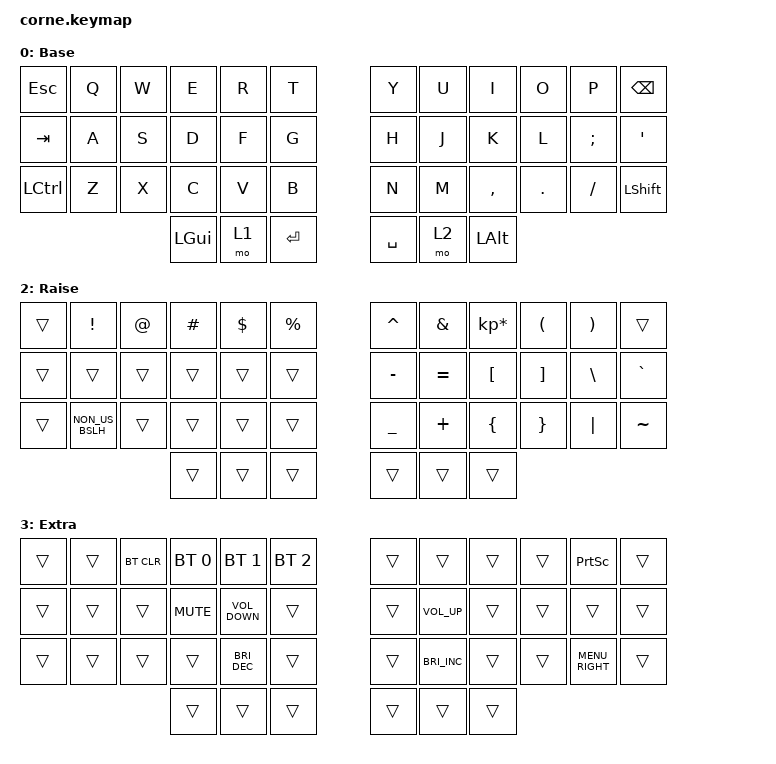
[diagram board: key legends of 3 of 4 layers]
/*
 * Copyright (c) 2020 The ZMK Contributors
 *
 * SPDX-License-Identifier: MIT
 */

#include <behaviors.dtsi>
#include <dt-bindings/zmk/bt.h>
#include <dt-bindings/zmk/keys.h>

/ {
    conditional_layers {
        compatible = "zmk,conditional-layers";

        tri_layer {
            if-layers = <1 2>;
            then-layer = <3>;
        };
    };
};

/ {
    keymap {
        compatible = "zmk,keymap";

        default_layer {
            // -----------------------------------------------------------------------------------------
            // |  TAB |  Q  |  W  |  E  |  R  |  T  |   |  Y  |  U   |  I  |  O  |  P  | BKSP |
            // | CTRL |  A  |  S  |  D  |  F  |  G  |   |  H  |  J   |  K  |  L  |  ;  |  '   |
            // | SHFT |  Z  |  X  |  C  |  V  |  B  |   |  N  |  M   |  ,  |  .  |  /  | ESC  |
            //                    | GUI | LWR | SPC |   | ENT | RSE  | ALT |

            display-name = "Base";
            bindings = <
&kp ESCAPE        &kp Q  &kp W  &kp E     &kp R  &kp T        &kp Y      &kp U  &kp I      &kp O    &kp P     &kp BSPC
&kp TAB           &kp A  &kp S  &kp D     &kp F  &kp G        &kp H      &kp J  &kp K      &kp L    &kp SEMI  &kp SQT
&kp LEFT_CONTROL  &kp Z  &kp X  &kp C     &kp V  &kp B        &kp N      &kp M  &kp COMMA  &kp DOT  &kp FSLH  &kp LSHIFT
                                &kp LGUI  &mo 1  &kp ENTER    &kp SPACE  &mo 2  &kp LALT
            >;
        };

        lower_layer {
            // -----------------------------------------------------------------------------------------
            // |  TAB |  1  |  2  |  3  |  4  |  5  |   |  6  |  7  |  8  |  9  |  0  | BKSP |
            // | BTCLR| BT1 | BT2 | BT3 | BT4 | BT5 |   | LFT | DWN |  UP | RGT |     |      |
            // | SHFT |     |     |     |     |     |   |     |     |     |     |     |      |
            //                    | GUI |     | SPC |   | ENT |     | ALT |

            display-name = "Lower";
            bindings = <
&trans  &kp N1  &kp N2  &kp N3  &kp N4  &kp N5    &kp N6    &kp N7         &kp N8       &kp N9     &kp N0  &kp DELETE
&trans  &trans  &trans  &trans  &trans  &trans    &kp LEFT  &kp DOWN       &kp UP       &kp RIGHT  &trans  &trans
&trans  &trans  &trans  &trans  &trans  &trans    &kp HOME  &kp PAGE_DOWN  &kp PAGE_UP  &kp END    &trans  &trans
                        &trans  &trans  &trans    &trans    &trans         &trans
&kp ESCAPE        &kp N1        &kp N2        &kp N3        &kp N4        &kp N5          &kp N6     &kp N7         &kp N8       &kp N9     &kp N0  &kp BSPC
&bt BT_CLR        &bt BT_SEL 0  &bt BT_SEL 1  &bt BT_SEL 2  &bt BT_SEL 3  &bt BT_SEL 4    &kp LEFT   &kp DOWN       &kp UP       &kp RIGHT  &trans  &trans
&kp LEFT_CONTROL  &trans        &trans        &trans        &trans        &trans          &kp HOME   &kp PAGE_DOWN  &kp PAGE_UP  &kp END    &trans  &trans
                                              &kp LGUI      &trans        &kp ENTER       &kp SPACE  &trans         &kp LALT
            >;
        };

        raise_layer {
            // -----------------------------------------------------------------------------------------
            // |  TAB |  !  |  @  |  #  |  $  |  %  |   |  ^  |  &  |  *  |  (  |  )  | BKSP |
            // | CTRL |     |     |     |     |     |   |  -  |  =  |  [  |  ]  |  \  |  `   |
            // | SHFT |     |     |     |     |     |   |  _  |  +  |  {  |  }  | "|" |  ~   |
            //                    | GUI |     | SPC |   | ENT |     | ALT |

            display-name = "Raise";
            bindings = <
&trans  &kp EXCL         &kp AT  &kp HASH  &kp DLLR  &kp PRCNT    &kp CARET  &kp AMPS   &kp KP_MULTIPLY  &kp LPAR  &kp RPAR  &trans
&trans  &trans           &trans  &trans    &trans    &trans       &kp MINUS  &kp EQUAL  &kp LBKT         &kp RBKT  &kp BSLH  &kp GRAVE
&trans  &kp NON_US_BSLH  &trans  &trans    &trans    &trans       &kp UNDER  &kp PLUS   &kp LBRC         &kp RBRC  &kp PIPE  &kp TILDE
                                 &trans    &trans    &trans       &trans     &trans     &trans
            >;
        };

        extra_layer {
            // -----------------------------------------------------------------------------------------
            // |  TAB |  1  |  2  |  3  |  4  |  5  |   |  6  |  7  |  8  |  9  |  0  | BKSP |
            // | BTCLR| BT1 | BT2 | BT3 | BT4 | BT5 |   | LFT | DWN |  UP | RGT |     |      |
            // | SHFT |     |     |     |     |     |   |     |     |     |     |     |      |
            //                    | GUI |     | SPC |   | ENT |     | ALT |

            display-name = "Extra";
            bindings = <
&trans  &trans  &bt BT_CLR    &bt BT_SEL 0  &bt BT_SEL 1          &bt BT_SEL 2    &trans  &trans                &trans  &trans  &kp PRINTSCREEN   &trans
&trans  &trans  &trans        &kp K_MUTE    &kp C_VOLUME_DOWN     &trans          &trans  &kp C_VOLUME_UP       &trans  &trans  &trans            &trans
&trans  &trans  &trans        &trans        &kp C_BRIGHTNESS_DEC  &trans          &trans  &kp C_BRIGHTNESS_INC  &trans  &trans  &kp C_MENU_RIGHT  &trans
                              &trans        &trans                &trans          &trans  &trans                &trans
            >;
        };

        extra_1 { status = "reserved"; };

        extra_2 { status = "reserved"; };

        extra_3 { status = "reserved"; };
    };
};
